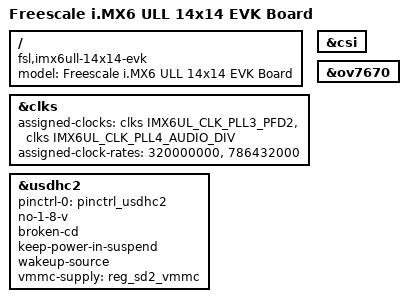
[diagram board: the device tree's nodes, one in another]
// SPDX-License-Identifier: (GPL-2.0 OR MIT)
//
// Copyright (C) 2016 Freescale Semiconductor, Inc.

/dts-v1/;

#include "imx6ull.dtsi"
#include "imx6ul-14x14-evk.dtsi"

/ {
	model = "Freescale i.MX6 ULL 14x14 EVK Board";
	compatible = "fsl,imx6ull-14x14-evk", "fsl,imx6ull";
};

&clks {
	assigned-clocks = <&clks IMX6UL_CLK_PLL3_PFD2>,
			  <&clks IMX6UL_CLK_PLL4_AUDIO_DIV>;
	assigned-clock-rates = <320000000>, <786432000>;
};

&usdhc2 {
	pinctrl-names = "default";
	pinctrl-0 = <&pinctrl_usdhc2>;
	no-1-8-v;
	broken-cd;
	keep-power-in-suspend;
	wakeup-source;
	// wifi-host;
	vmmc-supply = <&reg_sd2_vmmc>;
	status = "okay";
};

&csi {
	status = "okay";
};

&ov7670 {
	status = "okay";
};

/delete-node/ &sim2;
